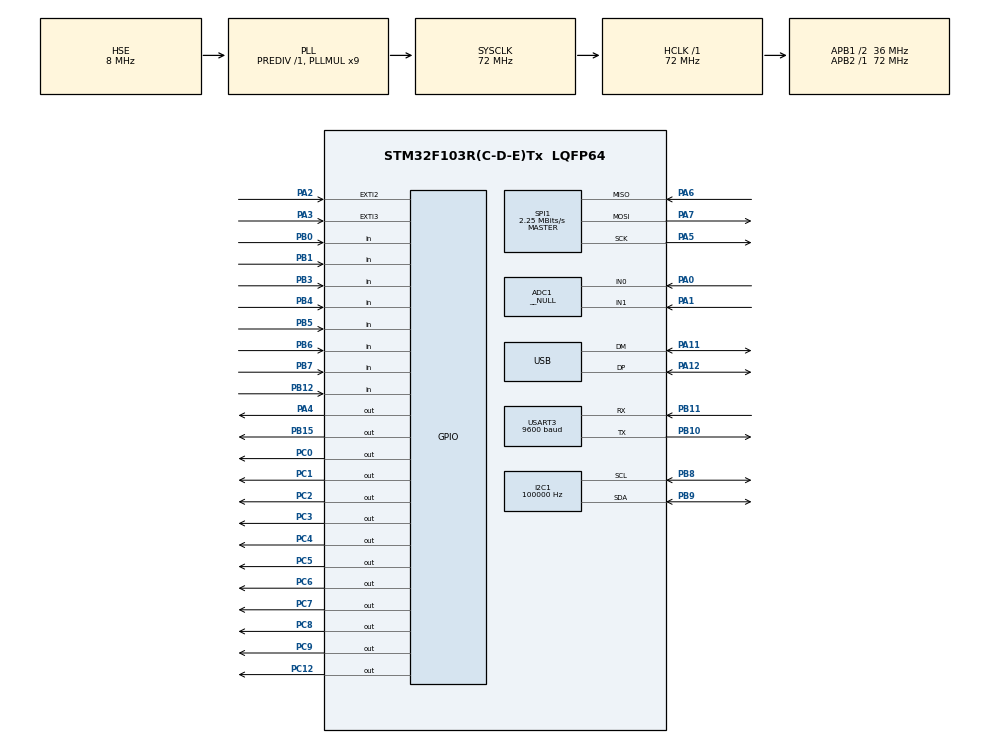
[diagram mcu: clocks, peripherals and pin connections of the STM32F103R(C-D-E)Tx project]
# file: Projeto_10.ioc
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ADC1.Channel-0\#ChannelRegularConversion=ADC_CHANNEL_0
ADC1.Channel-IN0=ADC_CHANNEL_0
ADC1.Channel-IN1=ADC_CHANNEL_1
ADC1.ContinuousConvMode=DISABLE
ADC1.DataAlign=ADC_DATAALIGN_RIGHT
ADC1.DiscontinuousConvMode=DISABLE
ADC1.EnableAnalogWatchDog=false
ADC1.EnableInjectedConversion=DISABLE
ADC1.EnableRegularConversion=ENABLE
ADC1.ExternalTrigConv=ADC_SOFTWARE_START
ADC1.Mode=__NULL
ADC1.NbrOfConversion=1
ADC1.Rank-0\#ChannelRegularConversion=1
ADC1.SamplingTime-0\#ChannelRegularConversion=ADC_SAMPLETIME_1CYCLE_5
ADC1.ScanConvMode=ADC_SCAN_DISABLE
ADC1.master=1
I2C1.AddressingMode=I2C_ADDRESSINGMODE_7BIT
I2C1.ClockSpeed=100000
I2C1.DualAddressMode=I2C_DUALADDRESS_DISABLE
I2C1.GeneralCallMode=I2C_GENERALCALL_DISABLE
I2C1.I2C_Mode=I2C_Standard
I2C1.NoStretchMode=I2C_NOSTRETCH_DISABLE
I2C1.OwnAddress=0
Mcu.Family=STM32F1
Mcu.Name=STM32F103R(C-D-E)Tx
Mcu.Package=LQFP64
NVIC.PriorityGroup=NVIC_PRIORITYGROUP_4
NVIC.USB_LP_CAN1_RX0_IRQn=true\:0\:0\:false\:false\:true\:false\:true
PA0-WKUP.Signal=ADCx_IN0
PA1.Signal=ADCx_IN1
PA11.Mode=Device
PA11.Signal=USB_DM
PA12.Mode=Device
PA12.Signal=USB_DP
PA13.Mode=Serial_Wire
PA13.Signal=SYS_JTMS-SWDIO
PA14.Mode=Serial_Wire
PA14.Signal=SYS_JTCK-SWCLK
PA2.Signal=GPXTI2
PA3.Signal=GPXTI3
PA4.GPIO_PuPd=GPIO_PULLUP
PA4.Signal=GPIO_Output
PA5.Mode=Full_Duplex_Master
PA5.Signal=SPI1_SCK
PA6.Mode=Full_Duplex_Master
PA6.Signal=SPI1_MISO
PA7.Mode=Full_Duplex_Master
PA7.Signal=SPI1_MOSI
PB0.Signal=GPIO_Input
PB1.Signal=GPIO_Input
PB10.Mode=Asynchronous
PB10.Signal=USART3_TX
PB11.Mode=Asynchronous
PB11.Signal=USART3_RX
PB12.Signal=GPIO_Input
PB15.Signal=GPIO_Output
PB3.Signal=GPIO_Input
PB4.Signal=GPIO_Input
PB5.Signal=GPIO_Input
PB6.Signal=GPIO_Input
PB7.Signal=GPIO_Input
PB8.Mode=I2C
PB8.Signal=I2C1_SCL
PB9.Mode=I2C
PB9.Signal=I2C1_SDA
PC0.Signal=GPIO_Output
PC1.Signal=GPIO_Output
PC12.Signal=GPIO_Output
PC14-OSC32_IN.Mode=LSE-External-Oscillator
PC14-OSC32_IN.Signal=RCC_OSC32_IN
PC15-OSC32_OUT.Mode=LSE-External-Oscillator
PC15-OSC32_OUT.Signal=RCC_OSC32_OUT
PC2.Signal=GPIO_Output
PC3.Signal=GPIO_Output
PC4.Signal=GPIO_Output
PC5.Signal=GPIO_Output
PC6.Signal=GPIO_Output
PC7.Signal=GPIO_Output
PC8.Signal=GPIO_Output
PC9.Signal=GPIO_Output
PD0-OSC_IN.Mode=HSE-External-Oscillator
PD0-OSC_IN.Signal=RCC_OSC_IN
PD1-OSC_OUT.Mode=HSE-External-Oscillator
PD1-OSC_OUT.Signal=RCC_OSC_OUT
ProjectManager.HeapSize=0x200
ProjectManager.StackSize=0x400
ProjectManager.TargetToolchain=MDK-ARM V5.27
RCC.ADCPresc=RCC_ADCPCLK2_DIV6
RCC.AHBFreq_Value=72000000
RCC.APB1CLKDivider=RCC_HCLK_DIV2
RCC.APB1Freq_Value=36000000
RCC.APB1TimFreq_Value=72000000
RCC.APB2Freq_Value=72000000
RCC.APB2TimFreq_Value=72000000
RCC.FLatency=FLASH_LATENCY_2
RCC.HCLKFreq_Value=72000000
RCC.PLLMUL=RCC_PLL_MUL9
RCC.SYSCLKFreq_VALUE=72000000
RCC.SYSCLKSource=RCC_SYSCLKSOURCE_PLLCLK
RCC.USBFreq_Value=48000000
RCC.USBPrescaler=RCC_USBCLKSOURCE_PLL_DIV1_5
SH.ADCx_IN0.0=ADC1_IN0,IN0
SH.ADCx_IN1.0=ADC1_IN1,IN1
SPI1.BaudRatePrescaler=SPI_BAUDRATEPRESCALER_32
SPI1.CLKPhase=SPI_PHASE_1EDGE
SPI1.CLKPolarity=SPI_POLARITY_LOW
SPI1.CRCCalculation=SPI_CRCCALCULATION_DISABLE
SPI1.CalculateBaudRate=2.25 MBits/s
SPI1.DataSize=SPI_DATASIZE_8BIT
SPI1.Direction=SPI_DIRECTION_2LINES
SPI1.FirstBit=SPI_FIRSTBIT_MSB
SPI1.Mode=SPI_MODE_MASTER
SPI1.NSS=SPI_NSS_SOFT
SPI1.TIMode=SPI_TIMODE_DISABLE
SPI1.VirtualType=VM_MASTER
USART3.BaudRate=9600
USART3.Mode=MODE_TX_RX
USART3.Parity=PARITY_NONE
USART3.StopBits=STOPBITS_1
USART3.VirtualMode=VM_ASYNC
USART3.WordLength=WORDLENGTH_8B
USB.DeviceSpeed=PCD_SPEED_FULL
USB.battery_charging_enable=DISABLE
USB.low_power_enable=DISABLE
USB.lpm_enable=DISABLE
USB_DEVICE.APP_RX_DATA_SIZE=1000
USB_DEVICE.APP_TX_DATA_SIZE=1000
USB_DEVICE.CLASS_NAME_FS=CDC
USB_DEVICE.CONFIGURATION_STRING_CDC_FS=CDC Config
USB_DEVICE.INTERFACE_STRING_CDC_FS=CDC Interface
USB_DEVICE.LANGID_STRING=1033
USB_DEVICE.MANUFACTURER_STRING=STMicroelectronics
USB_DEVICE.PID_CDC_FS=22336
USB_DEVICE.PRODUCT_STRING_CDC_FS=STM32 Virtual ComPort
USB_DEVICE.USBD_DEBUG_LEVEL=0
USB_DEVICE.USBD_MAX_NUM_CONFIGURATION=1
USB_DEVICE.USBD_MAX_NUM_INTERFACES=1
USB_DEVICE.USBD_MAX_STR_DESC_SIZ=512
USB_DEVICE.USBD_SELF_POWERED=1
USB_DEVICE.VID=1155
USB_DEVICE.VirtualMode=Cdc
USB_DEVICE.VirtualModeFS=Cdc_FS
VP_USB_DEVICE_VS_USB_DEVICE_CDC_FS.Mode=CDC_FS
board=custom

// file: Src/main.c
/* USER CODE BEGIN Header */
/**
  ******************************************************************************
  * @file           : main.c
  * @brief          : Main program body
  ******************************************************************************
  * @attention
  *
  * <h2><center>&copy; Copyright (c) 2021 STMicroelectronics.
  * All rights reserved.</center></h2>
  *
  * This software component is licensed by ST under Ultimate Liberty license
  * SLA0044, the "License"; You may not use this file except in compliance with
  * the License. You may obtain a copy of the License at:
  *                             www.st.com/SLA0044
  *
  ******************************************************************************
  */
/* USER CODE END Header */
#include "main.h"
#include "usb_device.h"
#include "uart_usb.h"
#include	"ethernet_clp.h"
#include  "ethernet_client.h"
#include  "ethernet_ssl.h"

ADC_HandleTypeDef hadc1;

I2C_HandleTypeDef hi2c1;

SPI_HandleTypeDef hspi1;

UART_HandleTypeDef huart3;

/* USER CODE BEGIN PV */
static  char request[] = "ola mundo";
uint8_t ip[4] = {192, 168, 15, 100};
uint8_t getway[4] = {192, 168, 15, 1};
/* USER CODE END PV */

void SystemClock_Config(void);
static void MX_GPIO_Init(void);
static void MX_SPI1_Init(void);
static void MX_ADC1_Init(void);
static void MX_I2C1_Init(void);
static void MX_USART3_UART_Init(void);

int main(void)
{

  /* MCU Configuration--------------------------------------------------------*/

  /* Reset of all peripherals, Initializes the Flash interface and the Systick. */
  HAL_Init();

  /* Configure the system clock */
  SystemClock_Config();

  /* Initialize all configured peripherals */
  MX_GPIO_Init();
  MX_SPI1_Init();
  MX_USB_DEVICE_Init();
  MX_ADC1_Init();
  MX_I2C1_Init();
  MX_USART3_UART_Init();
												init_ethernet_dinamico();
												//init_ethernet_estatico(ip, getway);

  /* USER CODE BEGIN 2 */
consulta_DNS();
init_ssl();
														////client_request(request);
  /* USER CODE END 2 */

  /* Infinite loop */
  while (1)
  {
			HAL_GPIO_TogglePin(GPIOC, GPIO_PIN_12);
		HAL_Delay(1000);
								////////////////////////     TCPLoopServer(); //  ----------------> MODO SERVIDOR TCP!

  }
}

void SystemClock_Config(void)
{
  RCC_OscInitTypeDef RCC_OscInitStruct = {0};
  RCC_ClkInitTypeDef RCC_ClkInitStruct = {0};
  RCC_PeriphCLKInitTypeDef PeriphClkInit = {0};

  /** Initializes the RCC Oscillators according to the specified parameters
  * in the RCC_OscInitTypeDef structure.
  */
  RCC_OscInitStruct.OscillatorType = RCC_OSCILLATORTYPE_HSE;
  RCC_OscInitStruct.HSEState = RCC_HSE_ON;
  RCC_OscInitStruct.HSEPredivValue = RCC_HSE_PREDIV_DIV1;
  RCC_OscInitStruct.HSIState = RCC_HSI_ON;
  RCC_OscInitStruct.PLL.PLLState = RCC_PLL_ON;
  RCC_OscInitStruct.PLL.PLLSource = RCC_PLLSOURCE_HSE;
  RCC_OscInitStruct.PLL.PLLMUL = RCC_PLL_MUL9;
  if (HAL_RCC_OscConfig(&RCC_OscInitStruct) != HAL_OK)
  {
    Error_Handler();
  }
  /** Initializes the CPU, AHB and APB buses clocks
  */
  RCC_ClkInitStruct.ClockType = RCC_CLOCKTYPE_HCLK|RCC_CLOCKTYPE_SYSCLK
                              |RCC_CLOCKTYPE_PCLK1|RCC_CLOCKTYPE_PCLK2;
  RCC_ClkInitStruct.SYSCLKSource = RCC_SYSCLKSOURCE_PLLCLK;
  RCC_ClkInitStruct.AHBCLKDivider = RCC_SYSCLK_DIV1;
  RCC_ClkInitStruct.APB1CLKDivider = RCC_HCLK_DIV2;
  RCC_ClkInitStruct.APB2CLKDivider = RCC_HCLK_DIV1;

  if (HAL_RCC_ClockConfig(&RCC_ClkInitStruct, FLASH_LATENCY_2) != HAL_OK)
  {
    Error_Handler();
  }
  PeriphClkInit.PeriphClockSelection = RCC_PERIPHCLK_ADC|RCC_PERIPHCLK_USB;
  PeriphClkInit.AdcClockSelection = RCC_ADCPCLK2_DIV6;
  PeriphClkInit.UsbClockSelection = RCC_USBCLKSOURCE_PLL_DIV1_5;
  if (HAL_RCCEx_PeriphCLKConfig(&PeriphClkInit) != HAL_OK)
  {
    Error_Handler();
  }
}

static void MX_ADC1_Init(void)
{

  ADC_ChannelConfTypeDef sConfig = {0};

  /** Common config
  */
  hadc1.Instance = ADC1;
  hadc1.Init.ScanConvMode = ADC_SCAN_DISABLE;
  hadc1.Init.ContinuousConvMode = DISABLE;
  hadc1.Init.DiscontinuousConvMode = DISABLE;
  hadc1.Init.ExternalTrigConv = ADC_SOFTWARE_START;
  hadc1.Init.DataAlign = ADC_DATAALIGN_RIGHT;
  hadc1.Init.NbrOfConversion = 1;
  if (HAL_ADC_Init(&hadc1) != HAL_OK)
  {
    Error_Handler();
  }
  /** Configure Regular Channel
  */
  sConfig.Channel = ADC_CHANNEL_0;
  sConfig.Rank = ADC_REGULAR_RANK_1;
  sConfig.SamplingTime = ADC_SAMPLETIME_1CYCLE_5;
  if (HAL_ADC_ConfigChannel(&hadc1, &sConfig) != HAL_OK)
  {
    Error_Handler();
  }

}

static void MX_I2C1_Init(void)
{

  hi2c1.Instance = I2C1;
  hi2c1.Init.ClockSpeed = 100000;
  hi2c1.Init.DutyCycle = I2C_DUTYCYCLE_2;
  hi2c1.Init.OwnAddress1 = 0;
  hi2c1.Init.AddressingMode = I2C_ADDRESSINGMODE_7BIT;
  hi2c1.Init.DualAddressMode = I2C_DUALADDRESS_DISABLE;
  hi2c1.Init.OwnAddress2 = 0;
  hi2c1.Init.GeneralCallMode = I2C_GENERALCALL_DISABLE;
  hi2c1.Init.NoStretchMode = I2C_NOSTRETCH_DISABLE;
  if (HAL_I2C_Init(&hi2c1) != HAL_OK)
  {
    Error_Handler();
  }

}

static void MX_SPI1_Init(void)
{

  /* SPI1 parameter configuration*/
  hspi1.Instance = SPI1;
  hspi1.Init.Mode = SPI_MODE_MASTER;
  hspi1.Init.Direction = SPI_DIRECTION_2LINES;
  hspi1.Init.DataSize = SPI_DATASIZE_8BIT;
  hspi1.Init.CLKPolarity = SPI_POLARITY_LOW;
  hspi1.Init.CLKPhase = SPI_PHASE_1EDGE;
  hspi1.Init.NSS = SPI_NSS_SOFT;
  hspi1.Init.BaudRatePrescaler = SPI_BAUDRATEPRESCALER_32;
  hspi1.Init.FirstBit = SPI_FIRSTBIT_MSB;
  hspi1.Init.TIMode = SPI_TIMODE_DISABLE;
  hspi1.Init.CRCCalculation = SPI_CRCCALCULATION_DISABLE;
  hspi1.Init.CRCPolynomial = 10;
  if (HAL_SPI_Init(&hspi1) != HAL_OK)
  {
    Error_Handler();
  }

}

static void MX_USART3_UART_Init(void)
{

  huart3.Instance = USART3;
  huart3.Init.BaudRate = 9600;
  huart3.Init.WordLength = UART_WORDLENGTH_8B;
  huart3.Init.StopBits = UART_STOPBITS_1;
  huart3.Init.Parity = UART_PARITY_NONE;
  huart3.Init.Mode = UART_MODE_TX_RX;
  huart3.Init.HwFlowCtl = UART_HWCONTROL_NONE;
  huart3.Init.OverSampling = UART_OVERSAMPLING_16;
  if (HAL_UART_Init(&huart3) != HAL_OK)
  {
    Error_Handler();
  }

}

static void MX_GPIO_Init(void)
{
  GPIO_InitTypeDef GPIO_InitStruct = {0};

  /* GPIO Ports Clock Enable */
  __HAL_RCC_GPIOC_CLK_ENABLE();
  __HAL_RCC_GPIOD_CLK_ENABLE();
  __HAL_RCC_GPIOA_CLK_ENABLE();
  __HAL_RCC_GPIOB_CLK_ENABLE();

  /*Configure GPIO pin Output Level */
  HAL_GPIO_WritePin(GPIOC, GPIO_PIN_0|GPIO_PIN_1|GPIO_PIN_2|GPIO_PIN_3
                          |GPIO_PIN_4|GPIO_PIN_5|GPIO_PIN_6|GPIO_PIN_7
                          |GPIO_PIN_8|GPIO_PIN_9|GPIO_PIN_12, GPIO_PIN_RESET);

  /*Configure GPIO pin Output Level */
  HAL_GPIO_WritePin(GPIOA, GPIO_PIN_4, GPIO_PIN_RESET);

  /*Configure GPIO pin Output Level */
  HAL_GPIO_WritePin(GPIOB, GPIO_PIN_15, GPIO_PIN_RESET);

  /*Configure GPIO pins : PC0 PC1 PC2 PC3
                           PC4 PC5 PC6 PC7
                           PC8 PC9 PC12 */
  GPIO_InitStruct.Pin = GPIO_PIN_0|GPIO_PIN_1|GPIO_PIN_2|GPIO_PIN_3
                          |GPIO_PIN_4|GPIO_PIN_5|GPIO_PIN_6|GPIO_PIN_7
                          |GPIO_PIN_8|GPIO_PIN_9|GPIO_PIN_12;
  GPIO_InitStruct.Mode = GPIO_MODE_OUTPUT_PP;
  GPIO_InitStruct.Pull = GPIO_NOPULL;
  GPIO_InitStruct.Speed = GPIO_SPEED_FREQ_LOW;
  HAL_GPIO_Init(GPIOC, &GPIO_InitStruct);

  /*Configure GPIO pins : PA2 PA3 */
  GPIO_InitStruct.Pin = GPIO_PIN_2|GPIO_PIN_3;
  GPIO_InitStruct.Mode = GPIO_MODE_IT_RISING;
  GPIO_InitStruct.Pull = GPIO_NOPULL;
  HAL_GPIO_Init(GPIOA, &GPIO_InitStruct);

  /*Configure GPIO pin : PA4 */
  GPIO_InitStruct.Pin = GPIO_PIN_4;
  GPIO_InitStruct.Mode = GPIO_MODE_OUTPUT_PP;
  GPIO_InitStruct.Pull = GPIO_PULLUP;
  GPIO_InitStruct.Speed = GPIO_SPEED_FREQ_LOW;
  HAL_GPIO_Init(GPIOA, &GPIO_InitStruct);

  /*Configure GPIO pins : PB0 PB1 PB12 PB3
                           PB4 PB5 PB6 PB7 */
  GPIO_InitStruct.Pin = GPIO_PIN_0|GPIO_PIN_1|GPIO_PIN_12|GPIO_PIN_3
                          |GPIO_PIN_4|GPIO_PIN_5|GPIO_PIN_6|GPIO_PIN_7;
  GPIO_InitStruct.Mode = GPIO_MODE_INPUT;
  GPIO_InitStruct.Pull = GPIO_NOPULL;
  HAL_GPIO_Init(GPIOB, &GPIO_InitStruct);

  /*Configure GPIO pin : PB15 */
  GPIO_InitStruct.Pin = GPIO_PIN_15;
  GPIO_InitStruct.Mode = GPIO_MODE_OUTPUT_PP;
  GPIO_InitStruct.Pull = GPIO_NOPULL;
  GPIO_InitStruct.Speed = GPIO_SPEED_FREQ_LOW;
  HAL_GPIO_Init(GPIOB, &GPIO_InitStruct);

}

void Error_Handler(void)
{
  __disable_irq();
  while (1)
  {
  }
}

/************************ (C) COPYRIGHT STMicroelectronics *****END OF FILE****/
